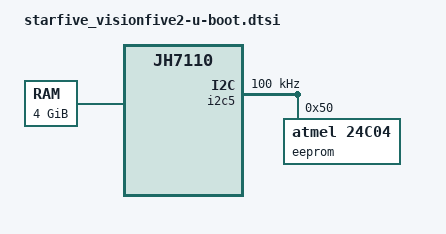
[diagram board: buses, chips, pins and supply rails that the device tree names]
// SPDX-License-Identifier: GPL-2.0 OR MIT
/*
 * Copyright (C) 2022 StarFive Technology Co., Ltd.
 */

#include "jh7110-u-boot.dtsi"
/ {
	chosen {
			stdout-path = "/soc/serial@10000000:115200";
			u-boot,dm-spl;
	};

	firmware {
		spi0="/soc/qspi@11860000";
		u-boot,dm-spl;
	};

	config {
		u-boot,dm-spl;
		u-boot,spl-payload-offset = <0x100000>; /* loader2 @1044KB */
	};

	memory@80000000 {
		u-boot,dm-spl;
		device_type = "memory";
		reg = <0x0 0x40000000 0x1 0x0>;
	};
};

&i2c5 {
	clock-frequency = <100000>;
	i2c-sda-hold-time-ns = <300>;
	i2c-sda-falling-time-ns = <3000>;
	i2c-scl-falling-time-ns = <3000>;
	auto_calc_scl_lhcnt;
	status = "okay";
	u-boot,dm-spl;

	eeprom@50 {
		compatible = "atmel,24c04";
		reg = <0x50>;
		pagesize = <16>;
		u-boot,dm-spl;
	};
};
